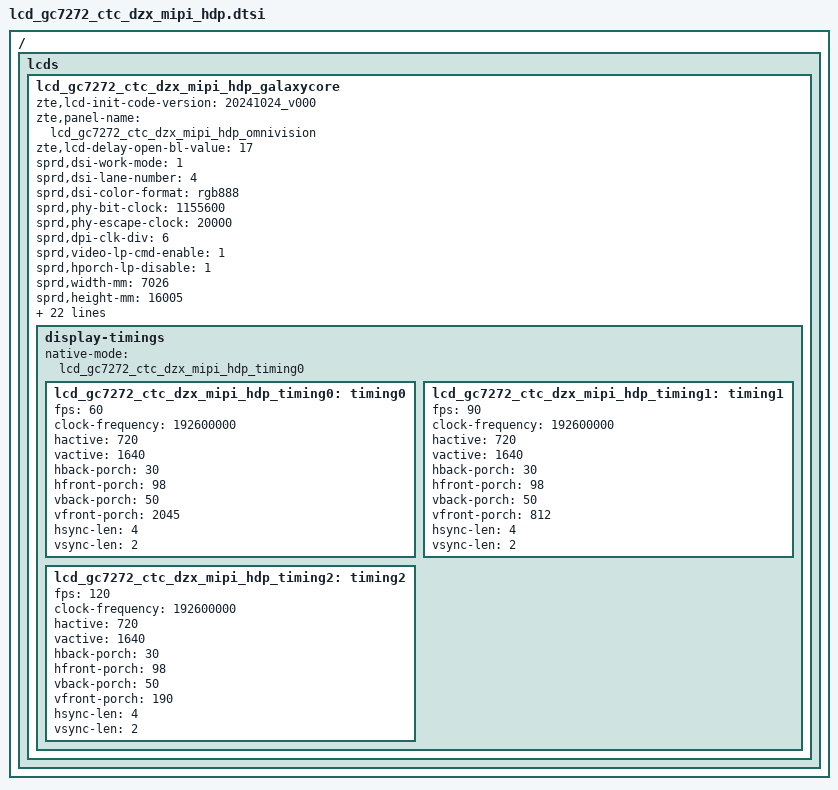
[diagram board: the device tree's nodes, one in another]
/ {
	fragment {
		target-path = "/";
		__overlay__ {
			lcds {
				lcd_gc7272_ctc_dzx_mipi_hdp_galaxycore:lcd_gc7272_ctc_dzx_mipi_hdp_galaxycore {
		zte,lcd-init-code-version = "20241024_v000";
		zte,panel-name = "lcd_gc7272_ctc_dzx_mipi_hdp_omnivision";
		zte,lcd-delay-open-bl-value = <17>;

					sprd,dsi-work-mode = <1>; /* video burst mode*/
					sprd,dsi-lane-number = <4>;
					sprd,dsi-color-format = "rgb888";

					sprd,phy-bit-clock = <1155600>;	/* kbps */ //128
					sprd,phy-escape-clock = <20000>;/* kHz */
					sprd,dpi-clk-div = <6>;
					sprd,video-lp-cmd-enable = <1>;
					sprd,hporch-lp-disable = <1>;
					sprd,width-mm = <7026>;/*zte mod for 6.67*/
					sprd,height-mm = <16005>;/*zte mod for 6.67*/
					sprd,esd-check-enable = <1>;/*esd enable:1*/
					sprd,esd-check-mode = <1>;/*esd te mode:1*/
					sprd,esd-check-period = <2000>;
					//sprd,esd-check-register = <0x0A>;
					//sprd,esd-check-value = <0x9C>;
					sprd,lcm-ic-name = "GC7272";
					sprd,lcm-ic-vendor = "DZX-CTC";
					sprd,lcm-ic-inch = "6.56";
					sprd,reset-on-sequence = <1 5>, <0 5>, <1 5>, <0 5>, <1 5>, <0 5>, <1 10>, <0 10>, <1 25>;
					sprd,reset-off-sequence = <1 20>;

					sprd,use-dcs-write;
				sprd,oled-brightness-close=[
				//13 32 00 01 28
				29 00 00 04 FF 55 AA 66
				23 00 00 02 FF 10
				13 32 00 01 28
				13 96 00 01 10
				23 00 00 02 FF 20
				23 00 00 02 4A 11
				23 00 00 02 FF 10
				13 78 00 01 11
				29 14 00 04 FF 66 99 55
			];
				sprd,oled-brightness-open=[
				//13 00 00 01 29
				29 00 00 04 FF 55 AA 66
				23 00 00 02 FF 10
				13 96 00 01 10
				23 00 00 02 FF 20
				23 00 00 02 4A 00
				23 00 00 02 FF 10
				13 78 00 01 11
				13 00 00 01 29
				29 14 00 04 FF 66 99 55
			];

					sprd,initial-command = [
39 00 00 04 FF 55 AA 66
23 00 00 02 FF 10
23 00 00 02 FB 00
23 00 00 02 FF 20
23 00 00 02 FB 00
23 00 00 02 FF 21
23 00 00 02 FB 00
23 00 00 02 FF 22
23 00 00 02 FB 00
23 00 00 02 FF 23
23 00 00 02 FB 00
23 00 00 02 FF 24
23 00 00 02 FB 00
23 00 00 02 FF 25
23 00 00 02 FB 00
23 00 00 02 FF 27
23 00 00 02 FB 00
23 00 00 02 FF 26
23 00 00 02 FB 00
23 00 00 02 FF 28
23 00 00 02 FB 00
23 00 00 02 FF A3
23 00 00 02 FB 00
23 00 00 02 FF B3
23 00 00 02 FB 00
23 00 00 02 FF 20
23 00 00 02 2D 55
23 00 00 02 AB 1F
23 00 00 02 AF 1F
23 00 00 02 FF B3
23 00 00 02 4E 46
23 00 00 02 FF B3
23 00 00 02 3F 37
23 00 00 02 50 10
23 00 00 02 FF 20
23 00 00 02 29 E0
23 00 00 02 20 84
23 00 00 02 21 00
23 00 00 02 22 80
23 00 00 02 2E 00
23 00 00 02 FF A3
23 00 00 02 58 AA
23 00 00 02 FF 26
23 00 00 02 43 00
23 00 00 02 FF A3
23 00 00 02 45 11
23 00 00 02 FF 20
23 00 00 02 4A 04
23 00 00 02 24 0A
23 00 00 02 48 10
23 00 00 02 49 00
23 00 00 02 FF 22
23 00 00 02 0E 33
23 00 00 02 0C 01
23 00 00 02 0B 6A
23 00 00 02 FF 28
23 00 00 02 7D 1F
23 00 00 02 7B 40
23 00 00 02 FF B3
23 00 00 02 47 01
23 00 00 02 FF 22
23 00 00 02 0D 02
23 00 00 02 FF B3
23 00 00 02 42 05
23 00 00 02 44 52
23 00 00 02 FF 22
23 00 00 02 E4 00
23 00 00 02 01 06
23 00 00 02 02 68
23 00 00 02 03 00
23 00 00 02 FF 20
23 00 00 02 C3 00
23 00 00 02 C4 7D
23 00 00 02 C7 00
23 00 00 02 C8 7D
23 00 00 02 B3 00
23 00 00 02 B4 32
23 00 00 02 B5 00
23 00 00 02 B6 BE
23 00 00 02 B7 00
23 00 00 02 B8 32
23 00 00 02 B9 00
23 00 00 02 BA BE
23 00 00 02 D3 03
23 00 00 02 D4 03
23 00 00 02 FF 22
23 00 00 02 25 07
23 00 00 02 2E 01
23 00 00 02 36 09
23 00 00 02 3F D5
23 00 00 02 83 07
23 00 00 02 8B 01
23 00 00 02 93 09
23 00 00 02 9B D5
23 00 00 02 FF 28
23 00 00 02 01 1A
23 00 00 02 02 25
23 00 00 02 03 25
23 00 00 02 04 1A
23 00 00 02 05 25
23 00 00 02 06 1E
23 00 00 02 07 1F
23 00 00 02 08 25
23 00 00 02 09 25
23 00 00 02 0A 09
23 00 00 02 0B 0B
23 00 00 02 0C 0D
23 00 00 02 0D 0F
23 00 00 02 0E 11
23 00 00 02 0F 13
23 00 00 02 10 01
23 00 00 02 11 03
23 00 00 02 12 05
23 00 00 02 13 25
23 00 00 02 14 19
23 00 00 02 15 25
23 00 00 02 16 25
23 00 00 02 17 25
23 00 00 02 18 1A
23 00 00 02 19 25
23 00 00 02 1A 1A
23 00 00 02 1B 25
23 00 00 02 1C 1E
23 00 00 02 1D 1f
23 00 00 02 1E 25
23 00 00 02 1F 25
23 00 00 02 20 08
23 00 00 02 21 0A
23 00 00 02 22 0C
23 00 00 02 23 0E
23 00 00 02 24 10
23 00 00 02 25 12
23 00 00 02 26 00
23 00 00 02 27 02
23 00 00 02 28 04
23 00 00 02 29 25
23 00 00 02 2A 19
23 00 00 02 2B 25
23 00 00 02 2D 25
23 00 00 02 30 00
23 00 00 02 31 55
23 00 00 02 32 00
23 00 00 02 33 05
23 00 00 02 34 00
23 00 00 02 35 15
23 00 00 02 36 00
23 00 00 02 37 55
23 00 00 02 38 00
23 00 00 02 39 01
23 00 00 02 2F 40
23 00 00 02 FF 21
23 00 00 02 29 00
23 00 00 02 7E 0F
23 00 00 02 7F 25
23 00 00 02 8B 25
23 00 00 02 97 25
23 00 00 02 A3 25
23 00 00 02 80 0B
23 00 00 02 8C 07
23 00 00 02 98 03
23 00 00 02 81 0B
23 00 00 02 8D 03
23 00 00 02 99 07
23 00 00 02 AF 40
23 00 00 02 B0 40
23 00 00 02 B1 40
23 00 00 02 B2 40
23 00 00 02 2B 00
23 00 00 02 83 04
23 00 00 02 8F 04
23 00 00 02 9B 04
23 00 00 02 84 4B
23 00 00 02 90 4B
23 00 00 02 9C 4B
23 00 00 02 85 55
23 00 00 02 91 55
23 00 00 02 9D 55
23 00 00 02 87 06
23 00 00 02 93 09
23 00 00 02 9F 02
23 00 00 02 22 06
23 00 00 02 23 09
23 00 00 02 24 02
23 00 00 02 82 B0
23 00 00 02 8E B0
23 00 00 02 9A B0
23 00 00 02 2E 01
23 00 00 02 88 97
23 00 00 02 89 10
23 00 00 02 8A 23
23 00 00 02 94 97
23 00 00 02 95 10
23 00 00 02 96 23
23 00 00 02 A0 97
23 00 00 02 A1 10
23 00 00 02 A2 23
23 00 00 02 45 FF
23 00 00 02 46 B6
23 00 00 02 4C B6
23 00 00 02 52 B6
23 00 00 02 58 B6
23 00 00 02 5E B6
23 00 00 02 64 B6
23 00 00 02 08 00
23 00 00 02 47 11
23 00 00 02 4D 10
23 00 00 02 53 0F
23 00 00 02 59 0E
23 00 00 02 5F 0D
23 00 00 02 65 0C
23 00 00 02 48 0C
23 00 00 02 4E 0D
23 00 00 02 54 0E
23 00 00 02 5A 0F
23 00 00 02 60 10
23 00 00 02 66 11
23 00 00 02 76 40
23 00 00 02 77 40
23 00 00 02 78 40
23 00 00 02 79 40
23 00 00 02 7A 40
23 00 00 02 7B 40
23 00 00 02 BE 03
23 00 00 02 C0 70
23 00 00 02 C1 42
23 00 00 02 BF BB
23 00 00 02 12 e0
23 00 00 02 13 12
23 00 00 02 14 A6
23 00 00 02 15 13
23 00 00 02 C2 8a
23 00 00 02 C6 72
23 00 00 02 B3 A7
23 00 00 02 B4 12
23 00 00 02 BB 77
23 00 00 02 BC 50
23 00 00 02 B5 A7
23 00 00 02 B6 12
23 00 00 02 B7 A6
23 00 00 02 B8 11
23 00 00 02 BB 77
23 00 00 02 BD 54
23 00 00 02 B9 A6
23 00 00 02 BA 11
23 00 00 02 FF 22
23 00 00 02 05 00
23 00 00 02 08 22
23 00 00 02 FF 28
23 00 00 02 3D 64
23 00 00 02 3E 64
23 00 00 02 3F 37
23 00 00 02 40 37
23 00 00 02 45 64
23 00 00 02 46 64
23 00 00 02 47 37
23 00 00 02 48 37
23 00 00 02 4D A2
23 00 00 02 50 2A
23 00 00 02 52 73
23 00 00 02 53 22
23 00 00 02 56 12
23 00 00 02 57 20
23 00 00 02 5A 7F
23 00 00 02 5B 7F
23 00 00 02 FF 21
23 00 00 02 49 70
23 00 00 02 4A 61
23 00 00 02 4F 70
23 00 00 02 50 61
23 00 00 02 55 70
23 00 00 02 56 61
23 00 00 02 5B 70
23 00 00 02 5C 61
23 00 00 02 61 70
23 00 00 02 62 61
23 00 00 02 67 70
23 00 00 02 68 61
23 00 00 02 6D 70
23 00 00 02 6E 61
23 00 00 02 73 70
23 00 00 02 74 61
23 00 00 02 84 23
23 00 00 02 85 59
23 00 00 02 90 23
23 00 00 02 91 59
23 00 00 02 9C 23
23 00 00 02 9D 59
23 00 00 02 A8 23
23 00 00 02 A9 59
23 00 00 02 E7 70
23 00 00 02 E8 61
23 00 00 02 E9 70
23 00 00 02 EA 61
23 00 00 02 EB 70
23 00 00 02 EC 61
23 00 00 02 ED 70
23 00 00 02 EE 61
23 00 00 02 F1 70
23 00 00 02 F2 61
23 00 00 02 F3 70
23 00 00 02 F4 61
23 00 00 02 F5 70
23 00 00 02 F6 61
23 00 00 02 F7 70
23 00 00 02 F8 61
23 00 00 02 D2 23
23 00 00 02 D3 59
23 00 00 02 D4 23
23 00 00 02 D5 59
23 00 00 02 D6 23
23 00 00 02 D7 59
23 00 00 02 D8 23
23 00 00 02 D9 59
23 00 00 02 FF 20
23 00 00 02 70 33
23 00 00 02 71 00
23 00 00 02 72 01
23 00 00 02 73 00
23 00 00 02 74 00
23 00 00 02 75 64
23 00 00 02 76 64
23 00 00 02 77 30
23 00 00 02 78 DC
23 00 00 02 79 30
23 00 00 02 7A DC
23 00 00 02 7C 0A
23 00 00 02 7D 0A
23 00 00 02 7E 33
23 00 00 02 7F 00
23 00 00 02 80 01
23 00 00 02 81 00
23 00 00 02 82 00
23 00 00 02 83 64
23 00 00 02 84 64
23 00 00 02 85 30
23 00 00 02 86 DC
23 00 00 02 87 30
23 00 00 02 88 DC
23 00 00 02 8A 0A
23 00 00 02 8B 0A
23 00 00 02 FF 25
23 00 00 02 75 32
23 00 00 02 76 00
23 00 00 02 77 01
23 00 00 02 78 00
23 00 00 02 79 01
23 00 00 02 7A 64
23 00 00 02 7B 64
23 00 00 02 7C 17
23 00 00 02 7D C8
23 00 00 02 7E 17
23 00 00 02 7F C8
23 00 00 02 80 00
23 00 00 02 81 0A
23 00 00 02 82 0A
23 00 00 02 85 32
23 00 00 02 86 00
23 00 00 02 87 01
23 00 00 02 88 00
23 00 00 02 89 01
23 00 00 02 8A 64
23 00 00 02 8B 64
23 00 00 02 8C 17
23 00 00 02 8D C8
23 00 00 02 8E 17
23 00 00 02 8F C8
23 00 00 02 90 00
23 00 00 02 91 0A
23 00 00 02 92 0A
23 00 00 02 FF 22
23 00 00 02 DC 00
23 00 00 02 E0 01
23 00 00 02 FF 23
23 00 00 02 EF 07
23 00 00 02 29 03
39 00 00 11 01 00 2B 00 32 00 57 00 76 00 92 00 A7 00 BA 00 CB
39 00 00 11 02 00 D8 01 0B 01 33 01 6E 01 9D 01 DA 02 0F 02 11
39 00 00 11 03 02 4E 02 9A 02 CB 03 0B 03 34 03 66 03 76 03 85
39 00 00 0D 04 03 95 03 A7 03 BB 03 D2 03 EC 03 FF
39 00 00 11 0D 00 2B 00 32 00 57 00 76 00 92 00 A7 00 BA 00 CB
39 00 00 11 0E 00 D8 01 0B 01 33 01 6E 01 9D 01 DA 02 0F 02 11
39 00 00 11 0F 02 4E 02 9A 02 CB 03 0B 03 34 03 66 03 76 03 85
39 00 00 0D 10 03 95 03 A7 03 BB 03 D2 03 EC 03 FF
23 00 00 02 FF 20
23 00 00 02 15 0F
23 00 00 02 16 A0
23 00 00 02 17 0A
23 00 00 02 18 28
23 00 00 02 19 07
23 00 00 02 1A D0
23 00 00 02 1B 03
23 00 00 02 1C E8
23 00 00 02 1D 00
23 00 00 02 1E 0A
23 00 00 02 FF 10
39 00 00 03 51 00 00
23 00 00 02 53 2c
23 00 00 02 55 00
23 00 00 02 36 08
23 00 00 02 69 01
23 00 00 02 35 00
23 00 00 02 BA 03
23 00 00 02 FF 10
23 64 00 02 11 00
23 0A 00 02 29 00
					];

					sprd,sleep-in-command = [
					39 00 00 04 FF 55 AA 66
					23 00 00 02 FF 10
					23 32 00 02 28 00
					23 78 00 02 10 00
					23 14 00 02 4F 01
					];

					sprd,sleep-in-command2= [
					39 00 00 04 FF 55 AA 66
					23 00 00 02 FF 10
					23 32 00 02 28 00
					23 78 00 02 10 00
					];

					sprd,sleep-out-command = [
						13 78 00 01 11
						13 64 00 01 29
					];

					display-timings {
						native-mode = <&lcd_gc7272_ctc_dzx_mipi_hdp_timing0>;
						lcd_gc7272_ctc_dzx_mipi_hdp_timing0: timing0 {
							fps = <60>;
							clock-frequency = <192600000>;
							hactive = <720>;
							vactive = <1640>;
							hback-porch = <30>;
							hfront-porch = <98>;
							vback-porch = <50>;
							vfront-porch = <2045>;
							hsync-len = <4>;
							vsync-len = <2>;
						};
						lcd_gc7272_ctc_dzx_mipi_hdp_timing1: timing1 {
							fps = <90>;
							clock-frequency = <192600000>;
							hactive = <720>;
							vactive = <1640>;
							hback-porch = <30>;
							hfront-porch = <98>;
							vback-porch = <50>;
							vfront-porch = <812>;
							hsync-len = <4>;
							vsync-len = <2>;
						};
							lcd_gc7272_ctc_dzx_mipi_hdp_timing2: timing2 {
							fps = <120>;
							clock-frequency = <192600000>;
							hactive = <720>;
							vactive = <1640>;
							hback-porch = <30>;
							hfront-porch = <98>;
							vback-porch = <50>;
							vfront-porch = <190>;
							hsync-len = <4>;
							vsync-len = <2>;
							};
					};
				};
			};
		};
	};
};

